# AT90PWM161 device description
Architecture: AVR8; Family: megaAVR
Registers are 8-bit, access not given, no defined reset value unless marked. A register's access mark holds for its fields unless they carry their own. Offsets are from the block's base; [hi:lo] are bit positions; {n}, {i} and the like mark numbered series; 'fields as' and 'values as' point back to an identical list.

## AC — Analog Comparator
Instances: AC 0x00
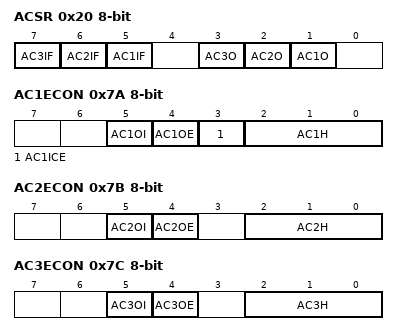
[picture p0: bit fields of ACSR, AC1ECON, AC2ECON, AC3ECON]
0x20 ACSR — Analog Comparator Status Register
  [7] AC3IF — Analog Comparator 3 Interrupt Flag Bit
  [6] AC2IF — Analog Comparator 2 Interrupt Flag Bit
  [5] AC1IF — Analog Comparator 1 Interrupt Flag Bit
  [3] AC3O — Analog Comparator 3 Output Bit
  [2] AC2O — Analog Comparator 2 Output Bit
  [1] AC1O — Analog Comparator 1 Output Bit
0x7A AC1ECON
  [5] AC1OI — Analog Comparator Ouput Invert
  [4] AC1OE — Analog Comparator Ouput Enable
  [3] AC1ICE — Analog Comparator Interrupt Capture Enable
  [2:0] AC1H — Analog Comparator Hysteresis Select
0x7B AC2ECON
  [5] AC2OI — Analog Comparator Ouput Invert
  [4] AC2OE — Analog Comparator Ouput Enable
  [2:0] AC2H — Analog Comparator Hysteresis Select
0x7C AC3ECON
  [5] AC3OI — Analog Comparator Ouput Invert
  [4] AC3OE — Analog Comparator Ouput Enable
  [2:0] AC3H — Analog Comparator Hysteresis Select
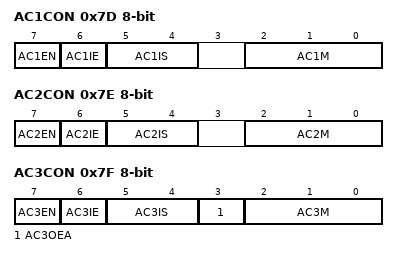
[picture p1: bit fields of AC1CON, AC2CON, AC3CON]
0x7D AC1CON — Analog Comparator 1 Control Register
  [7] AC1EN — Analog Comparator 1 Enable Bit
  [6] AC1IE — Analog Comparator 1 Interrupt Enable Bit
  [5:4] AC1IS — Analog Comparator 1 Interrupt Select Bit
    0=Interrupt on Toggle; 2=Interrupt on Falling Edge; 3=Interrupt on Rising Edge
  [2:0] AC1M — Analog Comparator 1 Multiplexer Register
0x7E AC2CON — Analog Comparator 2 Control Register
  [7] AC2EN — Analog Comparator 2 Enable Bit
  [6] AC2IE — Analog Comparator 2 Interrupt Enable Bit
  [5:4] AC2IS — Analog Comparator 2 Interrupt Select Bit
    values as AC1CON.AC1IS
  [2:0] AC2M — Analog Comparator 2 Multiplexer Register
0x7F AC3CON — Analog Comparator3 Control Register
  [7] AC3EN — Analog Comparator3 Enable Bit
  [6] AC3IE — Analog Comparator 3 Interrupt Enable Bit
  [5:4] AC3IS — Analog Comparator 3 Interrupt Select Bit
  [3] AC3OEA — Analog Comparator 3 Alternate Output Enable
  [2:0] AC3M — Analog Comparator 3 Multiplexer Register

## CPU — CPU Registers
Instances: CPU 0x00
Parameters: CORE_VERSION=V2E
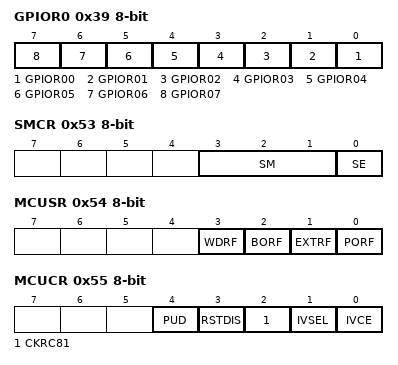
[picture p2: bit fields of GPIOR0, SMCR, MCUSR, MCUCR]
0x39 GPIOR0 — General Purpose IO Register 0
  [n] GPIOR{n:02} (n=0..7) — General Purpose IO Register 0 bit {n}
0x3A GPIOR1 — General Purpose IO Register 1
  [7:0] GPIOR (bit 10 of the value upward) — General Purpose IO Register 1 bis
0x3B GPIOR2 — General Purpose IO Register 2
  [7:0] GPIOR (bit 20 of the value upward) — General Purpose IO Register 2 bis
0x53 SMCR — Sleep Mode Control Register
  [3:1] SM — Sleep Mode Select bits
    0=IDLE; 1=ADC (ADC Noise Reduction (If Available)); 2=PDOWN (Power Down); 6=STDBY (Standby)
  [0] SE — Sleep Enable
0x54 MCUSR — MCU Status Register
  [3] WDRF — Watchdog Reset Flag
  [2] BORF — Brown-out Reset Flag
  [1] EXTRF — External Reset Flag
  [0] PORF — Power-on reset flag
0x55 MCUCR — MCU Control Register
  [4] PUD — Pull-up disable
  [3] RSTDIS — Reset Pin Disable
  [2] CKRC81 — Frequency Selection of the Calibrated RC Oscillator
  [1] IVSEL — Interrupt Vector Select
  [0] IVCE — Interrupt Vector Change Enable
0x5D SP 16-bit — Stack Pointer
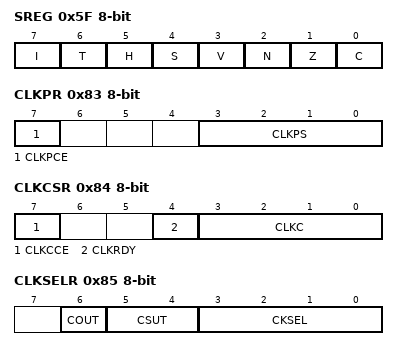
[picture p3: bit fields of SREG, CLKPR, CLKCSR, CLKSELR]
0x5F SREG — Status Register
  [7] I — Global Interrupt Enable
  [6] T — Bit Copy Storage
  [5] H — Half Carry Flag
  [4] S — Sign Bit
  [3] V — Two's Complement Overflow Flag
  [2] N — Negative Flag
  [1] Z — Zero Flag
  [0] C — Carry Flag
0x80 BGCRR — BandGap Resistor Calibration Register
  [3:0] BGCR
0x81 BGCCR — BandGap Current Calibration Register
  [3:0] BGCC
0x83 CLKPR
  [7] CLKPCE
  [3:0] CLKPS
    0=1; 1=2; 2=4; 3=8; 4=16; 5=32; 6=64; 7=128; 8=256
0x84 CLKCSR
  [7] CLKCCE — Clock Control Change Enable
  [4] CLKRDY — Clock Ready Flag
  [3:0] CLKC — Clock Control
0x85 CLKSELR
  [6] COUT — Clock OUT
  [5:4] CSUT — Clock Start up Time
  [3:0] CKSEL — Clock Source Select
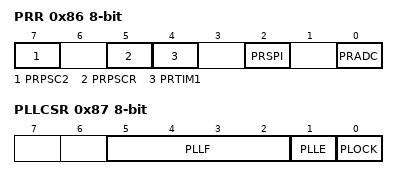
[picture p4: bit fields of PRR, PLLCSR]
0x86 PRR — Power Reduction Register
  [7] PRPSC2 — Power Reduction PSC2
  [5] PRPSCR — Power Reduction PSC0
  [4] PRTIM1 — Power Reduction Timer/Counter1
  [2] PRSPI — Power Reduction Serial Peripheral Interface
  [0] PRADC — Power Reduction ADC
0x87 PLLCSR — PLL Control And Status Register
  [5:2] PLLF
  [1] PLLE — PLL Enable
  [0] PLOCK — PLL Lock Detector
0x88 OSCCAL — Oscillator Calibration Value
  [7:0] OSCCAL — Oscillator Calibration
Value list OSCCAL_VALUE_ADDRESSES: 0=2_0_MHz; 1=8_0_MHz
